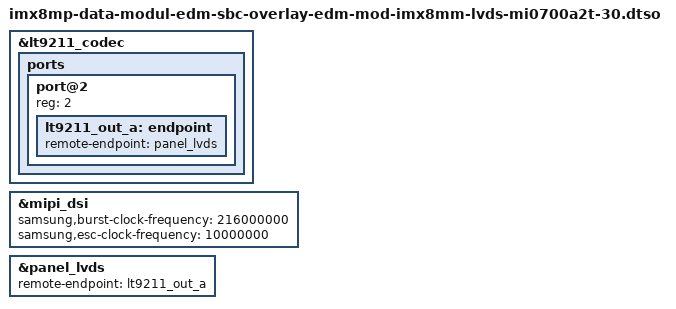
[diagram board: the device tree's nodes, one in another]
// SPDX-License-Identifier: (GPL-2.0+ OR MIT)
/*
 * Copyright 2024-2026 Marek Vasut
 */

#include "imx8mp-data-modul-edm-sbc-overlay-edm-mod-imx8mm-lvds.dtsi"
#include "imx8mp-data-modul-edm-sbc-overlay-lvds-mi0700a2t-30.dtsi"

&lt9211_codec {
	ports {
		port@2 {
			reg = <2>;

			lt9211_out_a: endpoint {
				remote-endpoint = <&panel_lvds>;
			};
		};
	};
};

&mipi_dsi {
	samsung,burst-clock-frequency = <216000000>;
	samsung,esc-clock-frequency = <10000000>;
};

&panel_lvds {
	remote-endpoint = <&lt9211_out_a>;
};
